VERSION ""

NS_ :

BS_:

BU_:
VAL_TABLE_ HIGH_VOLTAGE 1023 "Voltage Unknown" 1022 "Voltage Error" ;
VAL_TABLE_ PACK_CURRENT 2047 "Current Unknown" 2046 "Current Error" ;
VAL_TABLE_ ISOLATION 16383 "Isolation Unknown" 16382 "Isolation Error" ;
VAL_TABLE_ PDU_STATE_COMMAND 2 "Run" 1 "Sleep" 0 "No Change" ;
VAL_TABLE_ OPEN_CLOSE 1 "Close" 0 "Open" ;
VAL_TABLE_ HIGH_LOW 1 "High" 0 "Low" ;
VAL_TABLE_ PDU_STATE 3 "Fault" 2 "Run" 1 "Startup" 0 "Sleep" ;
VAL_TABLE_ FAULT 1 "Fault" 0 "OK" ;
VAL_TABLE_ ON_OFF 1 "On" 0 "Off" ;

BO_ 3221225472 VECTOR__INDEPENDENT_SIG_MSG: 0 Vector__XXX
 SG_ PDU_HV_HP_3_V_Sense : 0|10@1+ (1,0) [0|1023] "V" Vector__XXX

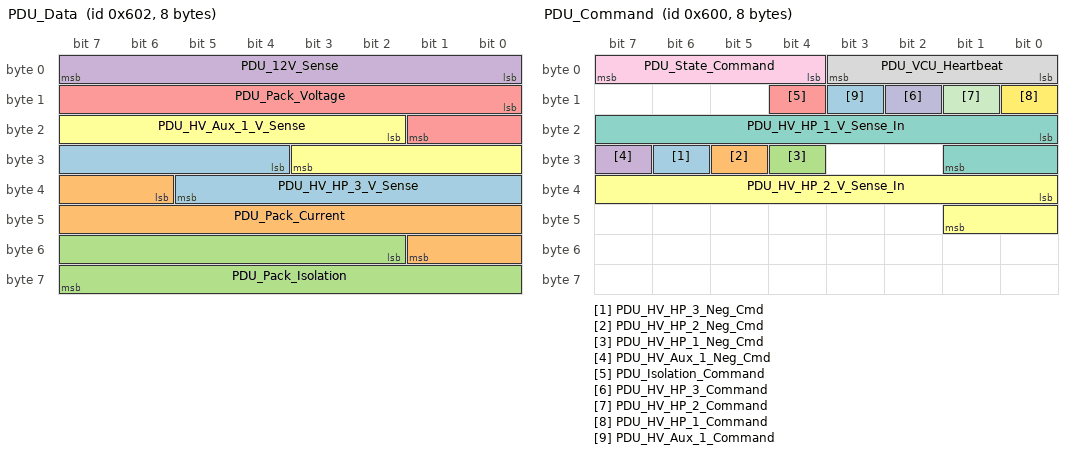
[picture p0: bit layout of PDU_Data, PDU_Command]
BO_ 1538 PDU_Data: 8 Vector__XXX
 SG_ PDU_HV_HP_3_V_Sense : 28|10@1+ (1,0) [0|1021] "V" Vector__XXX
 SG_ PDU_Pack_Current : 38|12@1- (1,0) [-2048|2045] "A" Vector__XXX
 SG_ PDU_Pack_Isolation : 50|14@1+ (1,0) [0|16381] "Ohm/V" Vector__XXX
 SG_ PDU_12V_Sense : 0|8@1+ (0.1,0) [0|25.5] "V" Vector__XXX
 SG_ PDU_Pack_Voltage : 8|10@1+ (1,0) [0|1021] "V" Vector__XXX
 SG_ PDU_HV_Aux_1_V_Sense : 18|10@1+ (1,0) [0|1021] "V" Vector__XXX

BO_ 1537 PDU_Status: 8 Vector__XXX
 SG_ PDU_Fault_Pack_Voltage : 54|1@1+ (1,0) [0|1] "" Vector__XXX
 SG_ PDU_Fault_Contactor_Power : 51|1@1+ (1,0) [0|1] "" Vector__XXX
 SG_ PDU_Warn_Cont_HV_HP_3 : 58|1@1+ (1,0) [0|1] "" Vector__XXX
 SG_ PDU_Warn_Cont_HV_HP_2 : 57|1@1+ (1,0) [0|1] "" Vector__XXX
 SG_ PDU_Warn_Cont_HV_HP_1 : 56|1@1+ (1,0) [0|1] "" Vector__XXX
 SG_ PDU_Warn_Pre_HV_HP_3 : 42|1@1+ (1,0) [0|1] "" Vector__XXX
 SG_ PDU_Warn_Pre_HV_HP_2 : 41|1@1+ (1,0) [0|1] "" Vector__XXX
 SG_ PDU_Warn_Pre_HV_HP_1 : 40|1@1+ (1,0) [0|1] "" Vector__XXX
 SG_ PDU_Warn_Pre_HV_Aux_1 : 43|1@1+ (1,0) [0|1] "" Vector__XXX
 SG_ PDU_Warn_Isolation : 44|1@1+ (1,0) [0|1] "" Vector__XXX
 SG_ PDU_Fault_HVIL_HP : 53|1@1+ (1,0) [0|1] "" Vector__XXX
 SG_ PDU_Fault_HVIL_Aux : 52|1@1+ (1,0) [0|1] "" Vector__XXX
 SG_ PDU_Warn_Cont_HV_Aux_1 : 59|1@1+ (1,0) [0|1] "" Vector__XXX
 SG_ PDU_Fault_Comm_VCU : 49|1@1+ (1,0) [0|1] "" Vector__XXX
 SG_ PDU_Warn_Comm_Isolation : 48|1@1+ (1,0) [0|1] "" Vector__XXX
 SG_ PDU_Fault_Comm_Current : 50|1@1+ (1,0) [0|1] "" Vector__XXX
 SG_ PDU_State : 4|4@1+ (1,0) [0|15] "" Vector__XXX
 SG_ PDU_Pre_HV_HP_3_Status : 26|1@1+ (1,0) [0|1] "" Vector__XXX
 SG_ PDU_Pre_HV_HP_2_Status : 25|1@1+ (1,0) [0|1] "" Vector__XXX
 SG_ PDU_Pre_HV_HP_1_Status : 24|1@1+ (1,0) [0|1] "" Vector__XXX
 SG_ PDU_Pre_HV_Aux_1_Status : 27|1@1+ (1,0) [0|1] "" Vector__XXX
 SG_ PDU_Key_Switch : 30|1@1+ (1,0) [0|1] "" Vector__XXX
 SG_ PDU_HV_HP_HVIL_Status : 29|1@1+ (1,0) [0|1] "" Vector__XXX
 SG_ PDU_Heartbeat : 0|4@1+ (1,0) [0|15] "" Vector__XXX
 SG_ PDU_Cont_HV_HP_3_Pos_Status : 21|1@1+ (1,0) [0|1] "" Vector__XXX
 SG_ PDU_Cont_HV_HP_3_Neg_Status : 20|1@1+ (1,0) [0|1] "" Vector__XXX
 SG_ PDU_Cont_HV_HP_2_Pos_Status : 19|1@1+ (1,0) [0|1] "" Vector__XXX
 SG_ PDU_Cont_HV_HP_2_Neg_Status : 18|1@1+ (1,0) [0|1] "" Vector__XXX
 SG_ PDU_Cont_HV_HP_1_Pos_Status : 17|1@1+ (1,0) [0|1] "" Vector__XXX
 SG_ PDU_Cont_HV_HP_1_Neg_Status : 16|1@1+ (1,0) [0|1] "" Vector__XXX
 SG_ PDU_Cont_HV_Aux_1_Pos_Status : 23|1@1+ (1,0) [0|1] "" Vector__XXX
 SG_ PDU_Cont_HV_Aux_1_Neg_Status : 22|1@1+ (1,0) [0|1] "" Vector__XXX
 SG_ PDU_Aux_Sense_HV_HP_3_Pos : 13|1@1+ (1,0) [0|1] "" Vector__XXX
 SG_ PDU_Aux_Sense_HV_HP_3_Neg : 12|1@1+ (1,0) [0|1] "" Vector__XXX
 SG_ PDU_Aux_Sense_HV_HP_2_Pos : 11|1@1+ (1,0) [0|1] "" Vector__XXX
 SG_ PDU_Aux_Sense_HV_HP_2_Neg : 10|1@1+ (1,0) [0|1] "" Vector__XXX
 SG_ PDU_Aux_Sense_HV_HP_1_Pos : 9|1@1+ (1,0) [0|1] "" Vector__XXX
 SG_ PDU_Aux_Sense_HV_HP_1_Neg : 8|1@1+ (1,0) [0|1] "" Vector__XXX
 SG_ PDU_Aux_Sense_HV_Aux_1_Pos : 15|1@1+ (1,0) [0|1] "" Vector__XXX
 SG_ PDU_Aux_Sense_HV_Aux_1_Neg : 14|1@1+ (1,0) [0|1] "" Vector__XXX
 SG_ PDU_HV_Aux_HVIL_Status : 28|1@1+ (1,0) [0|1] "" Vector__XXX

BO_ 1536 PDU_Command: 8 Vector__XXX
 SG_ PDU_HV_HP_3_Neg_Cmd : 30|1@1+ (1,0) [0|1] "" Vector__XXX
 SG_ PDU_HV_HP_2_Neg_Cmd : 29|1@1+ (1,0) [0|1] "" Vector__XXX
 SG_ PDU_HV_HP_1_Neg_Cmd : 28|1@1+ (1,0) [0|1] "" Vector__XXX
 SG_ PDU_HV_Aux_1_Neg_Cmd : 31|1@1+ (1,0) [0|1] "" Vector__XXX
 SG_ PDU_Isolation_Command : 12|1@1+ (1,0) [0|1] "" Vector__XXX
 SG_ PDU_HV_HP_2_V_Sense_In : 32|10@1+ (1,0) [0|1023] "V" Vector__XXX
 SG_ PDU_HV_HP_1_V_Sense_In : 16|10@1+ (1,0) [0|1023] "V" Vector__XXX
 SG_ PDU_VCU_Heartbeat : 0|4@1+ (1,0) [0|15] "" Vector__XXX
 SG_ PDU_State_Command : 4|4@1+ (1,0) [0|15] "" Vector__XXX
 SG_ PDU_HV_HP_3_Command : 10|1@1+ (1,0) [0|1] "" Vector__XXX
 SG_ PDU_HV_HP_2_Command : 9|1@1+ (1,0) [0|1] "" Vector__XXX
 SG_ PDU_HV_HP_1_Command : 8|1@1+ (1,0) [0|1] "" Vector__XXX
 SG_ PDU_HV_Aux_1_Command : 11|1@1+ (1,0) [0|1] "" Vector__XXX

CM_ BO_ 3221225472 "This is a message for not used signals, created by Vector CANdb++ DBC OLE DB Provider.";
CM_ SG_ 3221225472 PDU_HV_HP_3_V_Sense "The reported voltage of the HV HP 3 bus";
CM_ SG_ 1538 PDU_HV_HP_3_V_Sense "The reported voltage of the HV HP 3 bus post contactor";
CM_ SG_ 1538 PDU_HV_Aux_1_V_Sense "The reported voltage of the HV AUX 1 bus";
CM_ SG_ 1536 PDU_HV_HP_2_V_Sense_In "The reported voltage of the HV HP 2 bus";
CM_ SG_ 1536 PDU_HV_HP_1_V_Sense_In "The reported voltage of the HV HP 1 bus";
CM_ SG_ 1536 PDU_VCU_Heartbeat "This value increments with every VCU command message sent. Once the heartbeat reaches 15 it should roll over to 0. ";
CM_ SG_ 1536 PDU_State_Command "Sleep: all contactors are opened and contactors/precharge cannot be operated.
Run: Fault monitoring and contactors/precharge can be commanded.";
BA_DEF_  "BusType" STRING ;
BA_DEF_DEF_  "BusType" "CAN";
VAL_ 1538 PDU_HV_HP_3_V_Sense 1023 "Voltage Unknown" 1022 "Voltage Error" ;
VAL_ 1538 PDU_Pack_Current 2047 "Current Unknown" 2046 "Current Error" ;
VAL_ 1538 PDU_Pack_Isolation 16383 "Isolation Unknown" 16382 "Isolation Error" ;
VAL_ 1538 PDU_Pack_Voltage 1023 "Voltage Unknown" 1022 "Voltage Error" ;
VAL_ 1538 PDU_HV_Aux_1_V_Sense 1023 "Voltage Unknown" 1022 "Voltage Error" ;
VAL_ 1537 PDU_Fault_Pack_Voltage 1 "Fault" 0 "OK" ;
VAL_ 1537 PDU_Fault_Contactor_Power 1 "Fault" 0 "OK" ;
VAL_ 1537 PDU_Warn_Cont_HV_HP_3 1 "Fault" 0 "OK" ;
VAL_ 1537 PDU_Warn_Cont_HV_HP_2 1 "Fault" 0 "OK" ;
VAL_ 1537 PDU_Warn_Cont_HV_HP_1 1 "Fault" 0 "OK" ;
VAL_ 1537 PDU_Warn_Pre_HV_HP_3 1 "Fault" 0 "OK" ;
VAL_ 1537 PDU_Warn_Pre_HV_HP_2 1 "Fault" 0 "OK" ;
VAL_ 1537 PDU_Warn_Pre_HV_HP_1 1 "Fault" 0 "OK" ;
VAL_ 1537 PDU_Warn_Pre_HV_Aux_1 1 "Fault" 0 "OK" ;
VAL_ 1537 PDU_Warn_Isolation 1 "Fault" 0 "OK" ;
VAL_ 1537 PDU_Fault_HVIL_HP 1 "Fault" 0 "OK" ;
VAL_ 1537 PDU_Fault_HVIL_Aux 1 "Fault" 0 "OK" ;
VAL_ 1537 PDU_Warn_Cont_HV_Aux_1 1 "Fault" 0 "OK" ;
VAL_ 1537 PDU_Fault_Comm_VCU 1 "Fault" 0 "OK" ;
VAL_ 1537 PDU_Warn_Comm_Isolation 1 "Fault" 0 "OK" ;
VAL_ 1537 PDU_Fault_Comm_Current 1 "Fault" 0 "OK" ;
VAL_ 1537 PDU_State 3 "Fault" 2 "Run" 1 "Startup" 0 "Sleep" ;
VAL_ 1537 PDU_Pre_HV_HP_3_Status 1 "On" 0 "Off" ;
VAL_ 1537 PDU_Pre_HV_HP_2_Status 1 "On" 0 "Off" ;
VAL_ 1537 PDU_Pre_HV_HP_1_Status 1 "On" 0 "Off" ;
VAL_ 1537 PDU_Pre_HV_Aux_1_Status 1 "On" 0 "Off" ;
VAL_ 1537 PDU_Key_Switch 1 "On" 0 "Off" ;
VAL_ 1537 PDU_HV_HP_HVIL_Status 1 "High" 0 "Low" ;
VAL_ 1537 PDU_Cont_HV_HP_3_Pos_Status 1 "On" 0 "Off" ;
VAL_ 1537 PDU_Cont_HV_HP_3_Neg_Status 1 "On" 0 "Off" ;
VAL_ 1537 PDU_Cont_HV_HP_2_Pos_Status 1 "On" 0 "Off" ;
VAL_ 1537 PDU_Cont_HV_HP_2_Neg_Status 1 "On" 0 "Off" ;
VAL_ 1537 PDU_Cont_HV_HP_1_Pos_Status 1 "On" 0 "Off" ;
VAL_ 1537 PDU_Cont_HV_HP_1_Neg_Status 1 "On" 0 "Off" ;
VAL_ 1537 PDU_Cont_HV_Aux_1_Pos_Status 1 "On" 0 "Off" ;
VAL_ 1537 PDU_Cont_HV_Aux_1_Neg_Status 1 "On" 0 "Off" ;
VAL_ 1537 PDU_Aux_Sense_HV_HP_3_Pos 1 "High" 0 "Low" ;
VAL_ 1537 PDU_Aux_Sense_HV_HP_3_Neg 1 "High" 0 "Low" ;
VAL_ 1537 PDU_Aux_Sense_HV_HP_2_Pos 1 "High" 0 "Low" ;
VAL_ 1537 PDU_Aux_Sense_HV_HP_2_Neg 1 "High" 0 "Low" ;
VAL_ 1537 PDU_Aux_Sense_HV_HP_1_Pos 1 "High" 0 "Low" ;
VAL_ 1537 PDU_Aux_Sense_HV_HP_1_Neg 1 "High" 0 "Low" ;
VAL_ 1537 PDU_Aux_Sense_HV_Aux_1_Pos 1 "High" 0 "Low" ;
VAL_ 1537 PDU_Aux_Sense_HV_Aux_1_Neg 1 "High" 0 "Low" ;
VAL_ 1537 PDU_HV_Aux_HVIL_Status 1 "High" 0 "Low" ;
VAL_ 1536 PDU_HV_HP_3_Neg_Cmd 1 "Close" 0 "Open" ;
VAL_ 1536 PDU_HV_HP_2_Neg_Cmd 1 "Close" 0 "Open" ;
VAL_ 1536 PDU_HV_HP_1_Neg_Cmd 1 "Close" 0 "Open" ;
VAL_ 1536 PDU_HV_Aux_1_Neg_Cmd 1 "Close" 0 "Open" ;
VAL_ 1536 PDU_Isolation_Command 1 "On" 0 "Off" ;
VAL_ 1536 PDU_State_Command 2 "Run" 1 "Sleep" 0 "No Change" ;
VAL_ 1536 PDU_HV_HP_3_Command 1 "Close" 0 "Open" ;
VAL_ 1536 PDU_HV_HP_2_Command 1 "Close" 0 "Open" ;
VAL_ 1536 PDU_HV_HP_1_Command 1 "Close" 0 "Open" ;
VAL_ 1536 PDU_HV_Aux_1_Command 1 "Close" 0 "Open" ;
